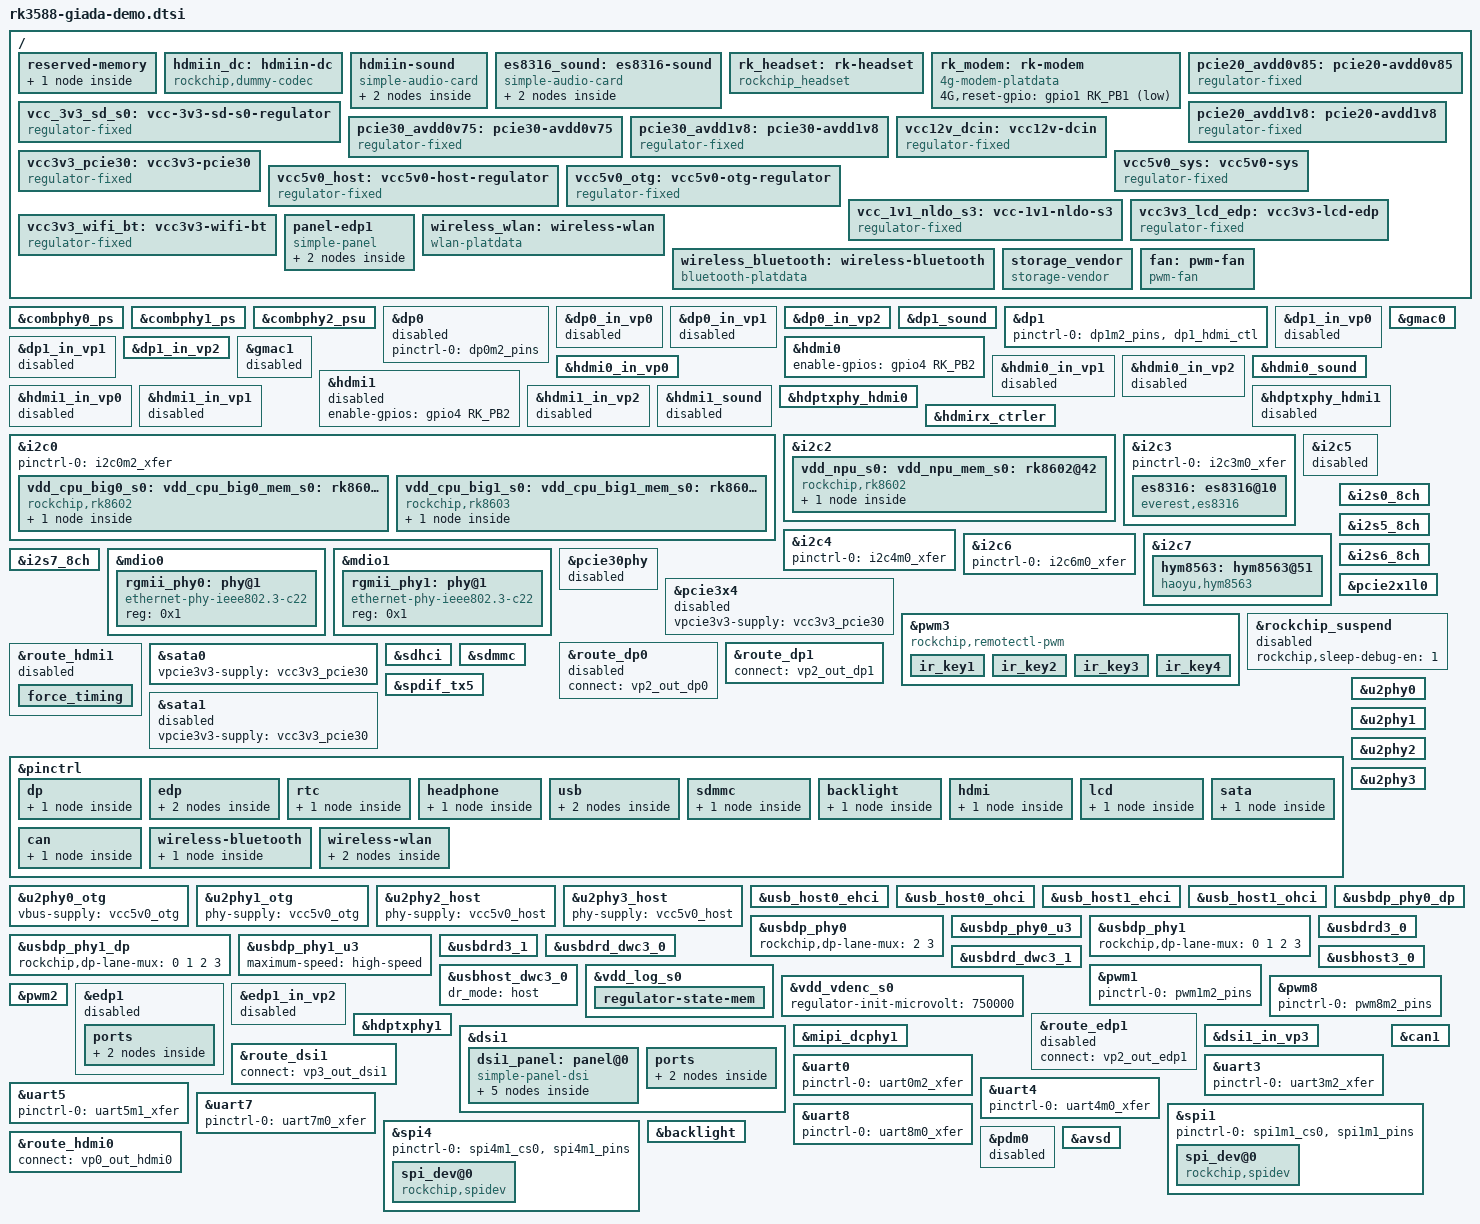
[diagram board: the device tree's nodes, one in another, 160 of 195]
// SPDX-License-Identifier: (GPL-2.0+ OR MIT)
/*
 * Copyright (c) 2021 Rockchip Electronics Co., Ltd.
 *
 */

#include "rk3588.dtsi"
#include "rk3588-giada.dtsi"
#include "rk3588-rk806-single.dtsi"

/ {
/* If hdmirx node is disabled, delete the reserved-memory node here. */
	reserved-memory {
		#address-cells = <2>;
		#size-cells = <2>;
		ranges;

		/* Reserve 128MB memory for hdmirx-controller@fdee0000 */
		cma {
			compatible = "shared-dma-pool";
			reusable;
			reg = <0x0 (256 * 0x100000) 0x0 (128 * 0x100000)>;
			linux,cma-default;
		};
	};

  hdmiin_dc: hdmiin-dc {
                compatible = "rockchip,dummy-codec";
                #sound-dai-cells = <0>;
        };

        hdmiin-sound {
                compatible = "simple-audio-card";
                simple-audio-card,format = "i2s";
                simple-audio-card,name = "rockchip,hdmiin";
                simple-audio-card,bitclock-master = <&dailink0_master>;
                simple-audio-card,frame-master = <&dailink0_master>;
                status = "okay";
                simple-audio-card,cpu {
                        sound-dai = <&i2s7_8ch>;
                };
                dailink0_master: simple-audio-card,codec {
                        sound-dai = <&hdmiin_dc>;
                };
        };


es8316_sound:es8316-sound {

                compatible = "simple-audio-card";
                simple-audio-card,format = "i2s";
                simple-audio-card,name = "rockchip,es8316-codec";
                simple-audio-card,mclk-fs = <256>;
                                 
                simple-audio-card,cpu {
                        sound-dai = <&i2s0_8ch>;
                };
                simple-audio-card,codec {
                        sound-dai = <&es8316>;
                };
   };
   
  
rk_headset: rk-headset {
		status = "okay";
		compatible = "rockchip_headset";
		headset_gpio = <&gpio4 RK_PA1 GPIO_ACTIVE_LOW>;
		mute_gpio = <&gpio4 RK_PA0 GPIO_ACTIVE_LOW>;
		pinctrl-names = "default";
		pinctrl-0 = <&hp_det>;
		io-channels = <&saradc 3>;
	};
rk_modem: rk-modem {
          compatible="4g-modem-platdata";
          pinctrl-names = "default";              
         
          4G,reset-gpio = <&gpio1 RK_PB1 GPIO_ACTIVE_LOW>;
          status = "okay";
        };
	
	/*leds: leds {
		compatible = "gpio-leds";
		hdd_led: hdd-led {
			gpios = <&gpio3 RK_PC1 GPIO_ACTIVE_HIGH>;
			default-state = "off";
		};
		net_led: net-led {
			gpios = <&gpio3 RK_PC0 GPIO_ACTIVE_HIGH>;
			default-state = "off";
		};
		work_led: work-led {
			gpios = <&gpio3 RK_PB7 GPIO_ACTIVE_HIGH>;
			linux,default-trigger = "heartbeat";
		};
	};*/
	
 vcc_3v3_sd_s0: vcc-3v3-sd-s0-regulator {
                compatible = "regulator-fixed";
                gpio = <&gpio3 RK_PA7 GPIO_ACTIVE_HIGH>;
                pinctrl-names = "default";
                pinctrl-0 = <&sd_s0_pwr>;
                regulator-name = "vcc_3v3_sd_s0";  
               vin-supply = <&vccio_sd_s0>;   
                      
                enable-active-high;
        };

	pcie20_avdd0v85: pcie20-avdd0v85 {
		compatible = "regulator-fixed";
		regulator-name = "pcie20_avdd0v85";
		regulator-boot-on;
		regulator-always-on;
		regulator-min-microvolt = <850000>;
		regulator-max-microvolt = <850000>;
		vin-supply = <&vdd_0v85_s0>;
	};

	pcie20_avdd1v8: pcie20-avdd1v8 {
		compatible = "regulator-fixed";
		regulator-name = "pcie20_avdd1v8";
		regulator-boot-on;
		regulator-always-on;
		regulator-min-microvolt = <1800000>;
		regulator-max-microvolt = <1800000>;
		vin-supply = <&avcc_1v8_s0>;
	};
	pcie30_avdd0v75: pcie30-avdd0v75 {
		compatible = "regulator-fixed";
		regulator-name = "pcie30_avdd0v75";
		regulator-boot-on;
		regulator-always-on;
		regulator-min-microvolt = <750000>;
		regulator-max-microvolt = <750000>;
		vin-supply = <&avdd_0v75_s0>;
	};

	pcie30_avdd1v8: pcie30-avdd1v8 {
		compatible = "regulator-fixed";
		regulator-name = "pcie30_avdd1v8";
		regulator-boot-on;
		regulator-always-on;
		regulator-min-microvolt = <1800000>;
		regulator-max-microvolt = <1800000>;
		vin-supply = <&avcc_1v8_s0>;
	};

	vcc12v_dcin: vcc12v-dcin {
		compatible = "regulator-fixed";
		regulator-name = "vcc12v_dcin";
		regulator-always-on;
		regulator-boot-on;
		regulator-min-microvolt = <12000000>;
		regulator-max-microvolt = <12000000>;
	};

	vcc3v3_pcie30: vcc3v3-pcie30 {
		compatible = "regulator-fixed";
		regulator-name = "vcc3v3_pcie30";
		regulator-min-microvolt = <3300000>;
		regulator-max-microvolt = <3300000>;
		enable-active-high;	 
		regulator-always-on;
		regulator-boot-on;
		gpios = <&gpio3 RK_PD5 GPIO_ACTIVE_HIGH>;
		startup-delay-us = <7500>;
		vin-supply = <&vcc12v_dcin>;
	};

	vcc5v0_sys: vcc5v0-sys {
		compatible = "regulator-fixed";
		regulator-name = "vcc5v0_sys";
		regulator-always-on;
		regulator-boot-on;
		regulator-min-microvolt = <5000000>;
		regulator-max-microvolt = <5000000>;
		vin-supply = <&vcc12v_dcin>;
	};

	vcc5v0_host: vcc5v0-host-regulator {
		compatible = "regulator-fixed";
		regulator-name = "vcc5v0_host";
		regulator-boot-on;
		regulator-always-on;
		regulator-min-microvolt = <5000000>;
		regulator-max-microvolt = <5000000>;
		enable-active-high;
		gpio = <&gpio3 RK_PB0 GPIO_ACTIVE_HIGH>;
		vin-supply = <&vcc5v0_sys>;
		pinctrl-names = "default";
		pinctrl-0 = <&vcc5v0_host_en>;
	};

	vcc5v0_otg: vcc5v0-otg-regulator {
		compatible = "regulator-fixed";
		regulator-name = "vcc5v0_otg";
		regulator-min-microvolt = <5000000>;
		regulator-max-microvolt = <5000000>;
		enable-active-high;
		gpio = <&gpio4 RK_PA7 GPIO_ACTIVE_HIGH>;
		vin-supply = <&vcc5v0_sys>;
		pinctrl-names = "default";
		pinctrl-0 = <&vcc5v0_otg_en>;
	};

	vcc_1v1_nldo_s3: vcc-1v1-nldo-s3 {
		compatible = "regulator-fixed";
		regulator-name = "vcc_1v1_nldo_s3";
		regulator-always-on;
		regulator-boot-on;
		regulator-min-microvolt = <1100000>;
		regulator-max-microvolt = <1100000>;
		vin-supply = <&vcc5v0_sys>;
	};
 
 vcc3v3_lcd_edp: vcc3v3-lcd-edp {
                compatible = "regulator-fixed";
                regulator-name = "vcc3v3_lcd_edp";
                regulator-always-on;
       //       gpio = <&gpio0 RK_PD3 GPIO_ACTIVE_HIGH>;
                pinctrl-names = "default";
                pinctrl-0 = <&edp_s3_pwr>;
                enable-active-high;
                vin-supply = <&vcc_3v3_s3>;
        };
  vcc3v3_wifi_bt: vcc3v3-wifi-bt {
                compatible = "regulator-fixed";
                regulator-name = "vcc3v3_wifi_bt";
                regulator-always-on;                
                pinctrl-names = "default";
                pinctrl-0 = <&wifi_poweren_gpio>;             
                
        };       
   panel-edp1 {
		compatible = "simple-panel";
		backlight = <&backlight>;
		power-supply = <&vcc3v3_lcd_edp>;
		prepare-delay-ms = <120>;
		enable-delay-ms = <120>;
		unprepare-delay-ms = <120>;
		disable-delay-ms = <120>;
		port {
           panel_in_edp1: endpoint {
           remote-endpoint = <&edp1_out_panel>;
          };
         };		
	}; 	
	wireless_wlan: wireless-wlan {
                compatible = "wlan-platdata";
                wifi_chip_type = "rtl8821cu";
                pinctrl-names = "default";
                pinctrl-0 = <&wifi_host_wake_irq>;
                WIFI,host_wake_irq = <&gpio1 RK_PB2 GPIO_ACTIVE_HIGH>;
             //   WIFI,poweren_gpio = <&gpio4 RK_PA2 GPIO_ACTIVE_HIGH>;
                status = "okay";
        };

 wireless_bluetooth: wireless-bluetooth {
                compatible = "bluetooth-platdata";                      
                 clocks = <&hym8563>;
                clock-names = "ext_clock";
                pinctrl-0 = <&bt_gpio>;  
              // uart_rts_gpios = <&gpio4 RK_PB6 GPIO_ACTIVE_LOW>;
		           pinctrl-names = "default";
             // BT,power_gpio = <&gpio4 RK_PB6 GPIO_ACTIVE_HIGH>;
                BT,wake_gpio     = <&gpio4 RK_PB4 GPIO_ACTIVE_HIGH>;
             //   BT,wake_host_irq = <&gpio1 RK_PB2 GPIO_ACTIVE_HIGH>;
                status = "okay";
        };
        
storage_vendor {
        compatible = "storage-vendor";
        status = "okay";
};

fan: pwm-fan {
  compatible = "pwm-fan";
  #cooling-cells = <2>;
  cooling-levels = <50 100 150 200 230 255>; 
 	pwms = <&pwm8 0 50000 0>;  
  rockchip,temp-trips = <
                        50000   1
                        55000   2
                        60000   3
                        65000   4
                        70000   5
                >;
   status = "okay";             
 
 };
        
};

&combphy0_ps {
	status = "okay";
};

&combphy1_ps {

	status = "okay";
};

&combphy2_psu {
	status = "okay";
};

&dp0 {
	pinctrl-0 = <&dp0m2_pins>;
	pinctrl-names = "default";
	status = "disabled";
};

&dp0_in_vp0 {
	status = "disabled";
};

&dp0_in_vp1 {
	status = "disabled";
};

&dp0_in_vp2 {
	status = "okay";
};
&es8316_sound {
        status = "okay";
};
&dp1_sound {
        status = "okay";
};

&dp1 {
	pinctrl-0 = <&dp1m2_pins &dp1_hdmi_ctl>;
	pinctrl-names = "default";
	status = "okay";
};

&dp1_in_vp0 {
	status = "disabled";
};

&dp1_in_vp1 {
	status = "disabled";
};

&dp1_in_vp2 {
	status = "okay";
};


&gmac0 {
	/* Use rgmii-rxid mode to disable rx delay inside Soc */
	phy-mode = "rgmii-rxid";
	clock_in_out = "output";

	snps,reset-gpio = <&gpio4 RK_PB3 GPIO_ACTIVE_LOW>;
	snps,reset-active-low;
	/* Reset time is 20ms, 100ms for rtl8211f */
	snps,reset-delays-us = <0 20000 100000>;

	pinctrl-names = "default";
	pinctrl-0 = <&gmac0_miim
		     &gmac0_tx_bus2
		     &gmac0_rx_bus2
		     &gmac0_rgmii_clk
		     &gmac0_rgmii_bus>;

	tx_delay = <0x44>;
	/* rx_delay = <0x4f>; */

	phy-handle = <&rgmii_phy0>;
	status = "okay";
};

&gmac1 {
	/* Use rgmii-rxid mode to disable rx delay inside Soc */
	phy-mode = "rgmii-rxid";
	clock_in_out = "output";

	snps,reset-gpio = <&gpio4 RK_PA2 GPIO_ACTIVE_LOW>;
	snps,reset-active-low;
	/* Reset time is 20ms, 100ms for rtl8211f */
	snps,reset-delays-us = <0 20000 100000>;

	pinctrl-names = "default";
	pinctrl-0 = <&gmac1_miim
		     &gmac1_tx_bus2
		     &gmac1_rx_bus2
		     &gmac1_rgmii_clk
		     &gmac1_rgmii_bus>;

	tx_delay = <0x42>;
	/* rx_delay = <0x4f>; */

	phy-handle = <&rgmii_phy1>;
	status = "disabled";
};

&hdmi0 {
	enable-gpios = <&gpio4 RK_PB2 GPIO_ACTIVE_HIGH>;
	status = "okay";
};

&hdmi0_in_vp0 {
	status = "okay";
};

&hdmi0_in_vp1 {
	status = "disabled";
};

&hdmi0_in_vp2 {
	status = "disabled";
};

&hdmi0_sound {
	status = "okay";
};

&hdmi1 {
	enable-gpios = <&gpio4 RK_PB2 GPIO_ACTIVE_HIGH>;
	status = "disabled";
};

&hdmi1_in_vp0 {
	status = "disabled";
};

&hdmi1_in_vp1 {
	status = "disabled";
};

&hdmi1_in_vp2 {
	status = "disabled";
};

&hdmi1_sound {
	status = "disabled";
};

&hdptxphy_hdmi0 {
	status = "okay";
};

&hdptxphy_hdmi1 {
	status = "disabled";
};
/* Should work with at least 128MB cma reserved above. */
&hdmirx_ctrler {
	status = "okay";

	/* Effective level used to trigger HPD: 0-low, 1-high */
	hpd-trigger-level = <0>;
	hdmirx-det-gpios = <&gpio1 RK_PD5 GPIO_ACTIVE_LOW>;
	pinctrl-names = "default";
	pinctrl-0 = <&hdmim1_rx &hdmirx_det>;
};

&i2c0 {
	status = "okay";
	pinctrl-names = "default";
	pinctrl-0 = <&i2c0m2_xfer>;

	vdd_cpu_big0_s0: vdd_cpu_big0_mem_s0: rk8602@42 {
		compatible = "rockchip,rk8602";
		reg = <0x42>;
		vin-supply = <&vcc5v0_sys>;
		regulator-compatible = "rk860x-reg";
		regulator-name = "vdd_cpu_big0_s0";
		regulator-min-microvolt = <550000>;
		regulator-max-microvolt = <1050000>;
		regulator-ramp-delay = <2300>;
		rockchip,suspend-voltage-selector = <1>;
		regulator-boot-on;
		regulator-always-on;
		regulator-state-mem {
			regulator-off-in-suspend;
		};
	};

	vdd_cpu_big1_s0: vdd_cpu_big1_mem_s0: rk8603@43 {
		compatible = "rockchip,rk8603";
		reg = <0x43>;
		vin-supply = <&vcc5v0_sys>;
		regulator-compatible = "rk860x-reg";
		regulator-name = "vdd_cpu_big1_s0";
		regulator-min-microvolt = <550000>;
		regulator-max-microvolt = <1050000>;
		regulator-ramp-delay = <2300>;
		rockchip,suspend-voltage-selector = <1>;
		regulator-boot-on;
		regulator-always-on;
		regulator-state-mem {
			regulator-off-in-suspend;
		};
	};
};

&i2c2 {
	status = "okay";

	vdd_npu_s0: vdd_npu_mem_s0: rk8602@42 {
		compatible = "rockchip,rk8602";
		reg = <0x42>;
		vin-supply = <&vcc5v0_sys>;
		regulator-compatible = "rk860x-reg";
		regulator-name = "vdd_npu_s0";
		regulator-min-microvolt = <550000>;
		regulator-max-microvolt = <950000>;
		regulator-ramp-delay = <2300>;
		rockchip,suspend-voltage-selector = <1>;
		regulator-boot-on;
		regulator-always-on;
		regulator-state-mem {
			regulator-off-in-suspend;
		};
	};
};

&i2c3 {
	  status = "okay";
	  pinctrl-names = "default";
	  pinctrl-0 = <&i2c3m0_xfer>;
    es8316: es8316@10 {
                status = "okay";
                #sound-dai-cells = <0>;
                compatible = "everest,es8316";
                reg = <0x10>;
                clocks = <&cru I2S0_8CH_MCLKOUT>;
                clock-names = "mclk";
                assigned-clocks = <&cru I2S0_8CH_MCLKOUT>;
                assigned-clock-rates = <12288000>;
                pinctrl-names = "default";
                pinctrl-0 = <&i2s0_mclk>;               
                     
              
        };
  
};

&i2c4 {
	status = "okay";
	pinctrl-names = "default";
	pinctrl-0 = <&i2c4m0_xfer>;
};

&i2c5 {
	status = "disabled";
};
&i2c6 {
	status = "okay";
	pinctrl-names = "default";
	pinctrl-0 = <&i2c6m0_xfer>;	
};
&i2c7 {
	status = "okay";
	hym8563: hym8563@51 {
		compatible = "haoyu,hym8563";
		reg = <0x51>;
    #clock-cells = <0>;
    clock-frequency = <32768>;
    clock-output-names = "hym8563";
		pinctrl-names = "default";
		pinctrl-0 = <&rtc_int>;
		interrupt-parent = <&gpio0>;
		interrupts = <RK_PB2 IRQ_TYPE_LEVEL_LOW>;
		wakeup-source;
	};
};

&i2s0_8ch {
	status = "okay";
	pinctrl-0 = <&i2s0_lrck
		     &i2s0_sclk
		     &i2s0_sdi0
		     &i2s0_sdo0>;
};

&i2s5_8ch {
	status = "okay";
};

&i2s6_8ch {
	status = "okay";
};

&i2s7_8ch {
 status = "okay";
};

&mdio0 {
	rgmii_phy0: phy@1 {
		compatible = "ethernet-phy-ieee802.3-c22";
		reg = <0x1>;
	};
};

&mdio1 {
	rgmii_phy1: phy@1 {
		compatible = "ethernet-phy-ieee802.3-c22";
		reg = <0x1>;
	};
};

&pcie30phy {
	status = "disabled";
};

&pcie3x4 {

	vpcie3v3-supply = <&vcc3v3_pcie30>;
	status = "disabled";
};
&pcie2x1l0 {
	 reset-gpios = <&gpio1 RK_PB4 GPIO_ACTIVE_HIGH>;
	 pinctrl-names = "default";
   pinctrl-0 = <&pcie30x1m2_pins>;
	status = "okay";
};

&pwm3 {
	compatible = "rockchip,remotectl-pwm";
	pinctrl-names = "default";
	pinctrl-0 = <&pwm3m0_pins>;
	remote_pwm_id = <3>;
	handle_cpu_id = <1>;
	remote_support_psci = <0>;
	status = "okay";

	ir_key1 {
		rockchip,usercode = <0x4040>;
		rockchip,key_table =
			<0xf2	KEY_REPLY>,
			<0xba	KEY_BACK>,
			<0xf4	KEY_UP>,
			<0xf1	KEY_DOWN>,
			<0xef	KEY_LEFT>,
			<0xee	KEY_RIGHT>,
			<0xbd	KEY_HOME>,
			<0xea	KEY_VOLUMEUP>,
			<0xe3	KEY_VOLUMEDOWN>,
			<0xe2	KEY_SEARCH>,
			<0xb2	KEY_POWER>,
			<0xbc	KEY_MUTE>,
			<0xec	KEY_MENU>,
			<0xbf	0x190>,
			<0xe0	0x191>,
			<0xe1	0x192>,
			<0xe9	183>,
			<0xe6	248>,
			<0xe8	185>,
			<0xe7	186>,
			<0xf0	388>,
			<0xbe	0x175>;
	};

	ir_key2 {
		rockchip,usercode = <0xff00>;
		rockchip,key_table =
			<0xf9	KEY_HOME>,
			<0xbf	KEY_BACK>,
			<0xfb	KEY_MENU>,
			<0xaa	KEY_REPLY>,
			<0xb9	KEY_UP>,
			<0xe9	KEY_DOWN>,
			<0xb8	KEY_LEFT>,
			<0xea	KEY_RIGHT>,
			<0xeb	KEY_VOLUMEDOWN>,
			<0xef	KEY_VOLUMEUP>,
			<0xf7	KEY_MUTE>,
			<0xe7	KEY_POWER>,
			<0xfc	KEY_POWER>,
			<0xa9	KEY_VOLUMEDOWN>,
			<0xa8	KEY_PLAYPAUSE>,
			<0xe0	KEY_VOLUMEDOWN>,
			<0xa5	KEY_VOLUMEDOWN>,
			<0xab	183>,
			<0xb7	388>,
			<0xe8	388>,
			<0xf8	184>,
			<0xaf	185>,
			<0xed	KEY_VOLUMEDOWN>,
			<0xee	186>,
			<0xb3	KEY_VOLUMEDOWN>,
			<0xf1	KEY_VOLUMEDOWN>,
			<0xf2	KEY_VOLUMEDOWN>,
			<0xf3	KEY_SEARCH>,
			<0xb4	KEY_VOLUMEDOWN>,
			<0xa4	KEY_SETUP>,
			<0xbe	KEY_SEARCH>;
	};

	ir_key3 {
		rockchip,usercode = <0x1dcc>;
		rockchip,key_table =
			<0xee	KEY_REPLY>,
			<0xf0	KEY_BACK>,
			<0xf8	KEY_UP>,
			<0xbb	KEY_DOWN>,
			<0xef	KEY_LEFT>,
			<0xed	KEY_RIGHT>,
			<0xfc	KEY_HOME>,
			<0xf1	KEY_VOLUMEUP>,
			<0xfd	KEY_VOLUMEDOWN>,
			<0xb7	KEY_SEARCH>,
			<0xff	KEY_POWER>,
			<0xf3	KEY_MUTE>,
			<0xbf	KEY_MENU>,
			<0xf9	0x191>,
			<0xf5	0x192>,
			<0xb3	388>,
			<0xbe	KEY_1>,
			<0xba	KEY_2>,
			<0xb2	KEY_3>,
			<0xbd	KEY_4>,
			<0xf9	KEY_5>,
			<0xb1	KEY_6>,
			<0xfc	KEY_7>,
			<0xf8	KEY_8>,
			<0xb0	KEY_9>,
			<0xb6	KEY_0>,
			<0xb5	KEY_BACKSPACE>;
	};

	ir_key4 {
                rockchip,usercode = <0xf708>;
		 rockchip,key_table =
                        <0xFF   KEY_POWER>,
                        <0xF4   KEY_MENU>,
                        <0xF6   KEY_BACK>,
                        <0xE9   KEY_HOME>,
                        <0xF1   KEY_ENTER>,
                        <0xEE   KEY_VOLUMEUP>,
                        <0xEB   KEY_VOLUMEDOWN>,
                        <0xE9   KEY_REPLY>,
                        <0xF3   KEY_UP>,
                        <0xEF   KEY_DOWN>,
                        <0xF2   KEY_LEFT>,
                        <0xF0   KEY_RIGHT>,
                        <0xFA   KEY_PLAY>,
                        <0xE6   KEY_PLAYCD>,
                        <0xE7   KEY_STOP>,
                        <0xEC   KEY_MUTE>,
                        <0xE5   KEY_1>,
                        <0xE4   KEY_2>,
                        <0xE3   KEY_3>,
                        <0xE2   KEY_4>,
                        <0xE1   KEY_5>,
                        <0xE0   KEY_6>,
                        <0xBF   KEY_7>,
                        <0xBE   KEY_8>,
                        <0xBD   KEY_9>,
                        <0xBB   KEY_0>,
                        <0xE8   KEY_APPSELECT>,
                        <0xBC   KEY_NUMERIC_STAR>,
                        <0xBA   KEY_NUMERIC_POUND>,
                        <0xB6   0x2e8>;
        };
};

/*&rk806single {
	pinctrl-names = "default", "pmic-power-off";
	pinctrl-0 = <&pmic_pins>, <&rk806_dvs1_null>, <&rk806_dvs2_null>, <&rk806_dvs3_null>;
	pinctrl-1 = <&rk806_dvs1_slp>, <&rk806_dvs2_null>, <&rk806_dvs3_null>;

	regulators {
		avcc_1v8_s0: PLDO_REG1 {
			regulator-always-on;
			regulator-boot-on;
			regulator-min-microvolt = <1800000>;
			regulator-max-microvolt = <1800000>;
			regulator-name = "avcc_1v8_s0";
			regulator-state-mem {
				regulator-on-in-suspend;
				regulator-suspend-microvolt = <1800000>;
			};
		};
	};
};*/

&rockchip_suspend {
	status = "disabled";
	rockchip,sleep-debug-en = <1>;
	/*rockchip,virtual-poweroff = <1>;
	rockchip,sleep-mode-config = <
		(0
		| RKPM_SLP_ARMOFF_DDRPD
		)
	>;
	rockchip,wakeup-config = <
		(0
		| RKPM_CPU0_WKUP_EN
		| RKPM_GPIO_WKUP_EN
		)
	>;*/
};

&route_dp0 {
	status = "disabled";
	force-output;
	connect = <&vp2_out_dp0>;

	force_timing {
		clock-frequency = <65000000>;
		hactive = <1024>;
		vactive = <768>;
		hfront-porch = <24>;
		hsync-len = <136>;
		hback-porch = <160>;
		vfront-porch = <3>;
		vsync-len = <6>;
		vback-porch = <29>;
		hsync-active = <0>;
		vsync-active = <0>;
		de-active = <0>;
		pixelclk-active = <0>;
	};

};

&route_dp1 {
	status = "disabled";
	force-output;
	connect = <&vp2_out_dp1>;

	force_timing {
		clock-frequency = <65000000>;
		hactive = <1024>;
		vactive = <768>;
		hfront-porch = <24>;
		hsync-len = <136>;
		hback-porch = <160>;
		vfront-porch = <3>;
		vsync-len = <6>;
		vback-porch = <29>;
		hsync-active = <0>;
		vsync-active = <0>;
		de-active = <0>;
		pixelclk-active = <0>;
	};

};



&route_hdmi1 {
	status = "disabled";
	force-output;
	connect = <&vp2_out_hdmi1>;

	force_timing {
		clock-frequency = <65000000>;
		hactive = <1024>;
		vactive = <768>;
		hfront-porch = <24>;
		hsync-len = <136>;
		hback-porch = <160>;
		vfront-porch = <3>;
		vsync-len = <6>;
		vback-porch = <29>;
		hsync-active = <0>;
		vsync-active = <0>;
		de-active = <0>;
		pixelclk-active = <0>;
	};

};

&sata0 {
	    status = "okay";
	    vpcie3v3-supply = <&vcc3v3_pcie30>;
	   
};

&sata1 {
	status = "disabled";
	vpcie3v3-supply = <&vcc3v3_pcie30>;
};

&sdhci {
	bus-width = <8>;
	no-sdio;
	no-sd;
	non-removable;
	max-frequency = <200000000>;
	mmc-hs400-1_8v;
	mmc-hs400-enhanced-strobe;
	status = "okay";
};

&sdmmc {
        status = "okay";       
        max-frequency = <150000000>;
        no-sdio;
        no-mmc;
        bus-width = <4>;
        cap-mmc-highspeed;
       cap-sd-highspeed;
       disable-wp;
       sd-uhs-sdr104;
       vqmmc-supply = <&vccio_sd_s0>;
       vmmc-supply = <&vcc_3v3_sd_s0>;
};

&spdif_tx5 {
	status = "okay";
};

&pinctrl {
	dp {
	       	dp1_hdmi_ctl: dp-hdmi-ctl {
			            //  rockchip,pins = <0 RK_PC5 RK_FUNC_GPIO &pcfg_pull_up>,
				            rockchip,pins = <3 RK_PB2 RK_FUNC_GPIO &pcfg_pull_up>;
	               	};
    	};    	
    	
  edp {
           edp1_hpd: edp1-hpd {
                     rockchip,pins = <1 RK_PA6 RK_FUNC_GPIO &pcfg_pull_none>;
                  };
      };
      
	rtc {
	         	rtc_int: rtc-int {
			               rockchip,pins = <0 RK_PB2 RK_FUNC_GPIO &pcfg_pull_up>;
		              };
	};
  headphone {
	        	hp_det: hp-det {
			                rockchip,pins = <4 RK_PA1 RK_FUNC_GPIO &pcfg_pull_none>,
			                                <4 RK_PA0 RK_FUNC_GPIO &pcfg_pull_none>;
			               
		              };
          	};
          	
	usb {
	        	vcc5v0_host_en: vcc5v0-host-en {
		                	rockchip,pins = <3 RK_PB0 RK_FUNC_GPIO &pcfg_pull_none>;
	            	};

	          vcc5v0_otg_en: vcc5v0-otg-en {
			               rockchip,pins = <4 RK_PA7 RK_FUNC_GPIO &pcfg_pull_none>;
		           };
	   };
  sdmmc {
               sd_s0_pwr: sd-s0-pwr {
                        rockchip,pins = <3 RK_PA7 RK_FUNC_GPIO &pcfg_pull_up>;
                      };
        };
   
 edp {
               edp_s3_pwr: edp-s3-pwr {
                        rockchip,pins = <0 RK_PD3 RK_FUNC_GPIO &pcfg_output_high>;
                      };
     };  
 backlight {
               backlight_s3_pwr: backlight-s3-pwr {
                        rockchip,pins = <0 RK_PC6 RK_FUNC_GPIO &pcfg_pull_none>;
                        };
          };          
 hdmi {
		           hdmirx_det: hdmirx-det {
	                  		rockchip,pins = <1 RK_PD5 RK_FUNC_GPIO &pcfg_pull_up>;
	                    	};
	   };
 lcd {
                lcd_rst_gpio: lcd-rst-gpio {
                        rockchip,pins = <0 RK_PC5 RK_FUNC_GPIO &pcfg_pull_up>;
                };
        };
	
	sata {
		sata0_pm_enable: sata0-pm-enable {
			rockchip,pins = <3 RK_PD5  RK_FUNC_GPIO &pcfg_output_high>;
		};
	/*	sata1_pm_reset: sata1-pm-reset {
			rockchip,pins = <4 RK_PA1 RK_FUNC_GPIO &pcfg_output_high>;
		};*/
	};
	 can {
                can_stb_gpio: can-stb-gpio {
                        rockchip,pins = <3 RK_PC3 RK_FUNC_GPIO &pcfg_output_low>;
                };
        };
   wireless-bluetooth {
                   bt_gpio: bt-gpio {
                        rockchip,pins =
                                <4 RK_PB4 RK_FUNC_GPIO &pcfg_pull_none>;  
                                                    
                               
                };
        };

   wireless-wlan {
                wifi_host_wake_irq: wifi-host-wake-irq {
                        rockchip,pins = <1 RK_PB2 RK_FUNC_GPIO &pcfg_pull_down>;
                };

                wifi_poweren_gpio: wifi-poweren-gpio {
                        rockchip,pins = <4 RK_PA2 RK_FUNC_GPIO &pcfg_output_high>,
                                        <4 RK_PB5 RK_FUNC_GPIO &pcfg_output_high>,
                                        <4 RK_PB6 RK_FUNC_GPIO &pcfg_output_high>;       
                                       
                                      
                };
        };
  
     
      
};

&u2phy0 {
	status = "okay";
};

&u2phy1 {
	status = "okay";
};

&u2phy2 {
	status = "okay";
};

&u2phy3 {
	status = "okay";
};

&u2phy0_otg {
	vbus-supply = <&vcc5v0_otg>;
	status = "okay";
};

&u2phy1_otg {
	phy-supply = <&vcc5v0_otg>;
	status = "okay";
};

&u2phy2_host {
	phy-supply = <&vcc5v0_host>;
	status = "okay";
};

&u2phy3_host {
	phy-supply = <&vcc5v0_host>;
	status = "okay";
};

&usb_host0_ehci {
	status = "okay";
};

&usb_host0_ohci {
	status = "okay";
};

&usb_host1_ehci {
	status = "okay";
};

&usb_host1_ohci {
	status = "okay";
};

&usbdp_phy0 {
	rockchip,dp-lane-mux = < 2 3 >;
	status = "okay";
};

&usbdp_phy0_dp {
	status = "okay";
};

&usbdp_phy0_u3 {
					status = "okay";
};

&usbdp_phy1 {
					rockchip,dp-lane-mux = < 0 1 2 3 >;
					status = "okay";
};

&usbdp_phy1_dp {
				  rockchip,dp-lane-mux = < 0 1 2 3 >;
					status = "okay";
							};

&usbdp_phy1_u3 {
	maximum-speed = "high-speed";
	status = "okay";
};

&usbdrd3_0 {
	status = "okay";
};

&usbdrd3_1 {
	status = "okay";
};

&usbdrd_dwc3_0 {
	dr_mode = "peripheral";
	status = "okay";
};

&usbdrd_dwc3_1 {
	dr_mode = "host";
	maximum-speed = "high-speed";
	status = "okay";
};

&usbhost3_0 {
	status = "okay";
};

&usbhost_dwc3_0 {
	dr_mode = "host";
	status = "okay";
};

&vdd_log_s0 {
	regulator-state-mem {
		regulator-on-in-suspend;
		regulator-suspend-microvolt = <750000>;
	};
};

&vdd_vdenc_s0 {
	regulator-init-microvolt = <750000>;
};

&pwm1 {
        status = "okay";
        pinctrl-0 = <&pwm1m2_pins>;
};

&pwm8 {
      	
			  pinctrl-0 = <&pwm8m2_pins>;     
        status = "okay";
          
};

&pwm2 {
       status = "okay";
};
        

&edp1 {
    
       status = "disabled";
       pinctrl-names = "default";
       pinctrl-0 = <&edp1_hpd>;
       hpd-gpios = <&gpio1 RK_PA6 GPIO_ACTIVE_HIGH>;  
         ports {
                port@1 {
                        reg = <1>;
                        edp1_out_panel: endpoint {
                                remote-endpoint = <&panel_in_edp1>;
                                                 };
                        };
                }; 
     
};


&edp1_in_vp2 {
        status = "disabled";
};

&hdptxphy1 {
        status = "okay";
};

&route_edp1{
        connect = <&vp2_out_edp1>;
        status = "disabled";
};
/*
 * mipi_dcphy1 needs to be enabled
 * when dsi1 is enabled
 */

&dsi1 {
	status = "okay";
	dsi1_panel:panel@0 {
		status = "okay";
		compatible = "simple-panel-dsi";
		reg = <0>;
		power-supply = <&vcc3v3_lcd_edp>; 
		reset-gpios = <&gpio0 RK_PC5 GPIO_ACTIVE_LOW>;
		pinctrl-names = "default";
		pinctrl-0 = <&lcd_rst_gpio>;
		backlight = <&backlight>;
		prepare-delay-ms = <60>;
		enable-delay-ms= <10>;
		reset-delay-ms = <20>;
	  init-delay-ms = <20>;
		unprepare-delay-ms = <0>;
		disable-delay-ms = <20>;
		dsi,flags = <(MIPI_DSI_MODE_VIDEO | MIPI_DSI_MODE_VIDEO_BURST |
			MIPI_DSI_MODE_LPM | MIPI_DSI_MODE_EOT_PACKET)>;
		dsi,format = <MIPI_DSI_FMT_RGB888>;
		dsi,lanes  = <4>;
    
		disp_timings1: display-timings {
			native-mode = <&dsi1_timing0>;
			dsi1_timing0: timing0 {
			  clock-frequency = <90000000>;
        hactive = <1920>;
        vactive = <1080>;
        hback-porch = <21>;
        hfront-porch = <120>;
        vback-porch = <18>;
        vfront-porch = <21>;
        hsync-len = <50>;
        vsync-len = <90>;
        hsync-active = <0>;
        vsync-active = <0>;
        de-active = <0>;
        pixelclk-active = <0>;
			};
		};

		ports {
			#address-cells = <1>;
			#size-cells = <0>;

			port@0 {
				reg = <0>;
				panel_in_dsi1: endpoint {
					remote-endpoint = <&dsi1_out_panel>;
				};
			};
		};
	};

	ports {
		#address-cells = <1>;
		#size-cells = <0>;

		port@1 {
			reg = <1>;
			dsi1_out_panel: endpoint {
				remote-endpoint = <&panel_in_dsi1>;
			};
		};
	};

};

&mipi_dcphy1 {
     status = "okay";
};

&dsi1_in_vp3 {
       status = "okay";
};

&route_dsi1 {
			status = "okay";
			connect = <&vp3_out_dsi1>;
};
&uart0 {
        status = "okay";
        pinctrl-names = "default";
        pinctrl-0 = <&uart0m2_xfer>;
};
&uart3 {
        status = "okay";
        pinctrl-names = "default";
        pinctrl-0 = <&uart3m2_xfer>;
};
&uart4 {
        status = "okay";
        pinctrl-names = "default";
        pinctrl-0 = <&uart4m0_xfer>;
};
&uart5 {
        status = "okay";
        pinctrl-names = "default";
        pinctrl-0 = <&uart5m1_xfer>;
};
&uart7 {
        status = "okay";
        pinctrl-names = "default";
        pinctrl-0 = <&uart7m0_xfer>;
};
&uart8 {
        status = "okay";
        pinctrl-names = "default";
        pinctrl-0 = <&uart8m0_xfer>;
};

&can1 {
			assigned-clocks = <&cru CLK_CAN1>;
			assigned-clock-rates = <200000000>;
			pinctrl-names = "default";
			pinctrl-0 = <&can1m0_pins &can_stb_gpio>;
			status = "okay";
};
&spi1 {
        status = "okay";
     		pinctrl-names = "default";
	     	pinctrl-0 = <&spi1m1_cs0 &spi1m1_pins>;
	     	 spi_dev@0 {
                compatible = "rockchip,spidev";
                reg = <0>;
                spi-max-frequency = <12000000>;
                spi-lsb-first;
        };

};
&spi4 {
        status = "okay";
     		pinctrl-names = "default";
	     	pinctrl-0 = <&spi4m1_cs0 &spi4m1_pins>;
	     	 spi_dev@0 {
                compatible = "rockchip,spidev";
                reg = <0>;
                spi-max-frequency = <12000000>;
                spi-lsb-first;
        };
};

&backlight {
					 pwms = <&pwm2 0 25000 0>;	
					 pinctrl-0 = <&backlight_s3_pwr>;    			
					 enable-gpios = <&gpio0 RK_PC6 GPIO_ACTIVE_HIGH>;
					 status = "okay";
};

&pdm0 {
        status = "disabled";
};

&avsd {
	status = "okay";
};


&route_dp0 {
	status = "disabled";
	connect = <&vp2_out_dp0>;
	/delete-property/ force-output;
	/delete-node/ force_timing;
};

&route_dp1 {
	status = "okay";
	connect = <&vp2_out_dp1>;
	/delete-property/ force-output;
	/delete-node/ force_timing;
};

&route_hdmi0 {
	status = "okay";
	connect = <&vp0_out_hdmi0>;
	/delete-property/ force-output;
	/delete-node/ force_timing;
};



&usbdrd_dwc3_0 {
	dr_mode = "otg";
	extcon = <&u2phy0>;
	status = "okay";
};
